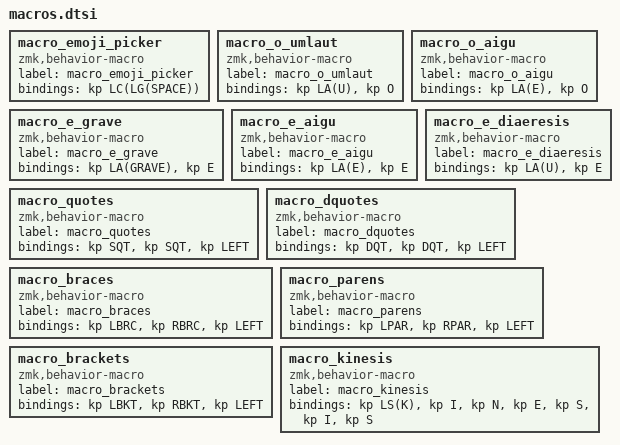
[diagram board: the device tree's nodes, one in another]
macro_emoji_picker: macro_emoji_picker{
compatible = "zmk,behavior-macro";
label = "macro_emoji_picker";
#binding-cells = <0>;
bindings = <&kp LC(LG(SPACE))>;
};
macro_o_umlaut: macro_o_umlaut{
compatible = "zmk,behavior-macro";
label = "macro_o_umlaut";
#binding-cells = <0>;
bindings = <&kp LA(U)>, <&kp O>;
};
macro_o_aigu: macro_o_aigu{
compatible = "zmk,behavior-macro";
label = "macro_o_aigu";
#binding-cells = <0>;
bindings = <&kp LA(E)>, <&kp O>;
};
macro_e_grave: macro_e_grave{
compatible = "zmk,behavior-macro";
label = "macro_e_grave";
#binding-cells = <0>;
bindings = <&kp LA(GRAVE)>, <&kp E>;
};
macro_e_aigu: macro_e_aigu{
compatible = "zmk,behavior-macro";
label = "macro_e_aigu";
#binding-cells = <0>;
bindings = <&kp LA(E)>, <&kp E>;
};
macro_e_diaeresis: macro_e_diaeresis{
compatible = "zmk,behavior-macro";
label = "macro_e_diaeresis";
#binding-cells = <0>;
bindings = <&kp LA(U)>, <&kp E>;
};
macro_quotes: macro_quotes{
compatible = "zmk,behavior-macro";
label = "macro_quotes";
#binding-cells = <0>;
bindings = <&kp SQT>, <&kp SQT>, <&kp LEFT>;
};
macro_dquotes: macro_dquotes{
compatible = "zmk,behavior-macro";
label = "macro_dquotes";
#binding-cells = <0>;
bindings = <&kp DQT>, <&kp DQT>, <&kp LEFT>;
};
macro_braces: macro_braces{
compatible = "zmk,behavior-macro";
label = "macro_braces";
#binding-cells = <0>;
bindings = <&kp LBRC>, <&kp RBRC>, <&kp LEFT>;
};
macro_parens: macro_parens{
compatible = "zmk,behavior-macro";
label = "macro_parens";
#binding-cells = <0>;
bindings = <&kp LPAR>, <&kp RPAR>, <&kp LEFT>;
};
macro_brackets: macro_brackets{
compatible = "zmk,behavior-macro";
label = "macro_brackets";
#binding-cells = <0>;
bindings = <&kp LBKT>, <&kp RBKT>, <&kp LEFT>;
};
macro_kinesis: macro_kinesis{
compatible = "zmk,behavior-macro";
label = "macro_kinesis";
#binding-cells = <0>;
bindings = <&kp LS(K)>, <&kp I>, <&kp N>, <&kp E>, <&kp S>, <&kp I>, <&kp S>;
};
